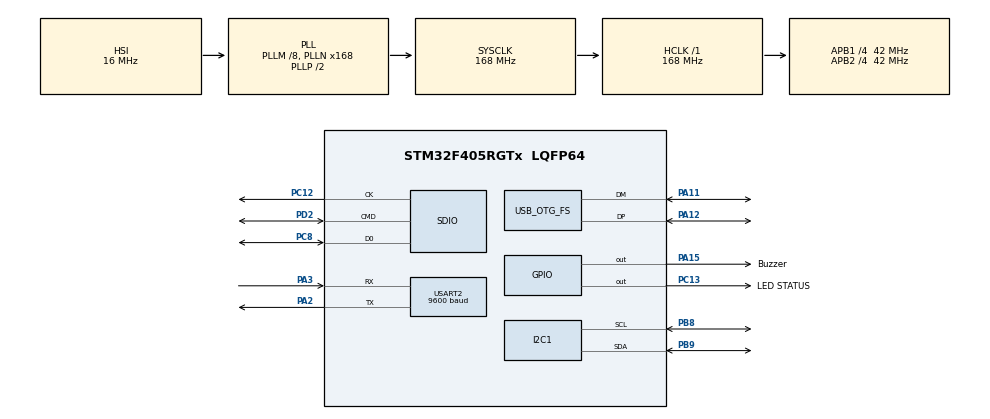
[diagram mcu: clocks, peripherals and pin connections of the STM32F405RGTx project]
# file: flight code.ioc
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Mcu.Family=STM32F4
Mcu.Name=STM32F405RGTx
Mcu.Package=LQFP64
NVIC.OTG_FS_IRQn=true\:0\:0\:false\:false\:true\:false\:true\:true
NVIC.PriorityGroup=NVIC_PRIORITYGROUP_4
NVIC.SDIO_IRQn=true\:0\:0\:false\:false\:true\:true\:true\:true
PA11.Mode=Device_Only
PA11.Signal=USB_OTG_FS_DM
PA12.Mode=Device_Only
PA12.Signal=USB_OTG_FS_DP
PA13.Mode=Serial_Wire
PA13.Signal=SYS_JTMS-SWDIO
PA14.Mode=Serial_Wire
PA14.Signal=SYS_JTCK-SWCLK
PA15.GPIO_Label=Buzzer
PA15.GPIO_ModeDefaultOutputPP=GPIO_MODE_OUTPUT_PP
PA15.Signal=GPIO_Output
PA2.Mode=Asynchronous
PA2.Signal=USART2_TX
PA3.Mode=Asynchronous
PA3.Signal=USART2_RX
PB8.Mode=I2C
PB8.Signal=I2C1_SCL
PB9.Mode=I2C
PB9.Signal=I2C1_SDA
PC12.Mode=SD_1_bit
PC12.Signal=SDIO_CK
PC13-ANTI_TAMP.GPIO_Label=LED STATUS
PC13-ANTI_TAMP.Signal=GPIO_Output
PC8.GPIO_PuPd=GPIO_PULLUP
PC8.Mode=SD_1_bit
PC8.Signal=SDIO_D0
PD2.GPIO_PuPd=GPIO_PULLUP
PD2.Mode=SD_1_bit
PD2.Signal=SDIO_CMD
ProjectManager.HeapSize=0x200
ProjectManager.StackSize=0x400
ProjectManager.TargetToolchain=STM32CubeIDE
RCC.48MHZClocksFreq_Value=48000000
RCC.AHBFreq_Value=168000000
RCC.APB1CLKDivider=RCC_HCLK_DIV4
RCC.APB1Freq_Value=42000000
RCC.APB1TimFreq_Value=84000000
RCC.APB2CLKDivider=RCC_HCLK_DIV4
RCC.APB2Freq_Value=42000000
RCC.APB2TimFreq_Value=84000000
RCC.CortexFreq_Value=168000000
RCC.HCLKFreq_Value=168000000
RCC.HSE_VALUE=8000000
RCC.HSI_VALUE=16000000
RCC.LSE_VALUE=32768
RCC.PLLM=8
RCC.PLLN=168
RCC.PLLQ=7
RCC.PLLSource=RCC_PLLSOURCE_HSI
RCC.SYSCLKFreq_VALUE=168000000
RCC.SYSCLKSource=RCC_SYSCLKSOURCE_PLLCLK
RCC.VCOOutputFreq_Value=336000000
SDIO.ClockDiv=118
USART2.BaudRate=9600
USART2.VirtualMode=VM_ASYNC
USB_DEVICE.CLASS_NAME_FS=CDC
USB_DEVICE.VirtualMode-CDC_FS=Cdc
USB_DEVICE.VirtualModeFS=Cdc_FS
USB_OTG_FS.VirtualMode=Device_Only
VP_FATFS_VS_SDIO.Mode=SDIO
VP_USB_DEVICE_VS_USB_DEVICE_CDC_FS.Mode=CDC_FS
board=custom

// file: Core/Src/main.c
/* USER CODE BEGIN Header */
/**
  ******************************************************************************
  * @file           : main.c
  * @brief          : Main program body
  ******************************************************************************
  * @attention
  *
  * Copyright (c) 2026 STMicroelectronics.
  * All rights reserved.
  *
  * This software is licensed under terms that can be found in the LICENSE file
  * in the root directory of this software component.
  * If no LICENSE file comes with this software, it is provided AS-IS.
  *
  ******************************************************************************
  */
/* USER CODE END Header */
#include "main.h"
#include "usb_device.h"
#include "usbd_cdc_if.h"
#include "flight_app.h"
#include <stdio.h>
#include "fatfs.h"

I2C_HandleTypeDef hi2c1;

SD_HandleTypeDef hsd;

UART_HandleTypeDef huart2;

void SystemClock_Config(void);
static void MX_GPIO_Init(void);
static void MX_I2C1_Init(void);
static void MX_USART2_UART_Init(void);
static void MX_SDIO_SD_Init(void);

/* USER CODE BEGIN 0 */
int _write(int file, char *ptr, int len)
{
    uint32_t start = HAL_GetTick();

    while (CDC_Transmit_FS((uint8_t *)ptr, len) == USBD_BUSY)
    {
        if ((HAL_GetTick() - start) > 20U)
        {
            /* Drop message if USB is busy too long */
            return len;
        }
    }
    return len;
}

/* USER CODE END 0 */

int main(void)
{

  /* MCU Configuration--------------------------------------------------------*/

  /* Reset of all peripherals, Initializes the Flash interface and the Systick. */
  HAL_Init();

  /* Configure the system clock */
  SystemClock_Config();

  /* Initialize all configured peripherals */
  MX_GPIO_Init();
  MX_USB_DEVICE_Init();
  MX_I2C1_Init();
  MX_USART2_UART_Init();
  MX_SDIO_SD_Init();
  MX_FATFS_Init();
  /* USER CODE BEGIN 2 */
  HAL_Delay(2000);

  printf("Booting flight project...\r\n");

  /* Start application layer */
  FlightApp_Init();
  /* USER CODE END 2 */

  /* Infinite loop */
  while (1)
  {
	  FlightApp_Run();
  }
}

void SystemClock_Config(void)
{
  RCC_OscInitTypeDef RCC_OscInitStruct = {0};
  RCC_ClkInitTypeDef RCC_ClkInitStruct = {0};

  /** Configure the main internal regulator output voltage
  */
  __HAL_RCC_PWR_CLK_ENABLE();
  __HAL_PWR_VOLTAGESCALING_CONFIG(PWR_REGULATOR_VOLTAGE_SCALE1);

  /** Initializes the RCC Oscillators according to the specified parameters
  * in the RCC_OscInitTypeDef structure.
  */
  RCC_OscInitStruct.OscillatorType = RCC_OSCILLATORTYPE_HSI;
  RCC_OscInitStruct.HSIState = RCC_HSI_ON;
  RCC_OscInitStruct.HSICalibrationValue = RCC_HSICALIBRATION_DEFAULT;
  RCC_OscInitStruct.PLL.PLLState = RCC_PLL_ON;
  RCC_OscInitStruct.PLL.PLLSource = RCC_PLLSOURCE_HSI;
  RCC_OscInitStruct.PLL.PLLM = 8;
  RCC_OscInitStruct.PLL.PLLN = 168;
  RCC_OscInitStruct.PLL.PLLP = RCC_PLLP_DIV2;
  RCC_OscInitStruct.PLL.PLLQ = 7;
  if (HAL_RCC_OscConfig(&RCC_OscInitStruct) != HAL_OK)
  {
    Error_Handler();
  }

  /** Initializes the CPU, AHB and APB buses clocks
  */
  RCC_ClkInitStruct.ClockType = RCC_CLOCKTYPE_HCLK|RCC_CLOCKTYPE_SYSCLK
                              |RCC_CLOCKTYPE_PCLK1|RCC_CLOCKTYPE_PCLK2;
  RCC_ClkInitStruct.SYSCLKSource = RCC_SYSCLKSOURCE_PLLCLK;
  RCC_ClkInitStruct.AHBCLKDivider = RCC_SYSCLK_DIV1;
  RCC_ClkInitStruct.APB1CLKDivider = RCC_HCLK_DIV4;
  RCC_ClkInitStruct.APB2CLKDivider = RCC_HCLK_DIV4;

  if (HAL_RCC_ClockConfig(&RCC_ClkInitStruct, FLASH_LATENCY_5) != HAL_OK)
  {
    Error_Handler();
  }
}

static void MX_I2C1_Init(void)
{

  hi2c1.Instance = I2C1;
  hi2c1.Init.ClockSpeed = 100000;
  hi2c1.Init.DutyCycle = I2C_DUTYCYCLE_2;
  hi2c1.Init.OwnAddress1 = 0;
  hi2c1.Init.AddressingMode = I2C_ADDRESSINGMODE_7BIT;
  hi2c1.Init.DualAddressMode = I2C_DUALADDRESS_DISABLE;
  hi2c1.Init.OwnAddress2 = 0;
  hi2c1.Init.GeneralCallMode = I2C_GENERALCALL_DISABLE;
  hi2c1.Init.NoStretchMode = I2C_NOSTRETCH_DISABLE;
  if (HAL_I2C_Init(&hi2c1) != HAL_OK)
  {
    Error_Handler();
  }

}

static void MX_SDIO_SD_Init(void)
{

  hsd.Instance = SDIO;
  hsd.Init.ClockEdge = SDIO_CLOCK_EDGE_RISING;
  hsd.Init.ClockBypass = SDIO_CLOCK_BYPASS_DISABLE;
  hsd.Init.ClockPowerSave = SDIO_CLOCK_POWER_SAVE_DISABLE;
  hsd.Init.BusWide = SDIO_BUS_WIDE_1B;
  hsd.Init.HardwareFlowControl = SDIO_HARDWARE_FLOW_CONTROL_DISABLE;
  hsd.Init.ClockDiv = 118;

}

static void MX_USART2_UART_Init(void)
{

  huart2.Instance = USART2;
  huart2.Init.BaudRate = 9600;
  huart2.Init.WordLength = UART_WORDLENGTH_8B;
  huart2.Init.StopBits = UART_STOPBITS_1;
  huart2.Init.Parity = UART_PARITY_NONE;
  huart2.Init.Mode = UART_MODE_TX_RX;
  huart2.Init.HwFlowCtl = UART_HWCONTROL_NONE;
  huart2.Init.OverSampling = UART_OVERSAMPLING_16;
  if (HAL_UART_Init(&huart2) != HAL_OK)
  {
    Error_Handler();
  }

}

static void MX_GPIO_Init(void)
{
  GPIO_InitTypeDef GPIO_InitStruct = {0};

  /* GPIO Ports Clock Enable */
  __HAL_RCC_GPIOC_CLK_ENABLE();
  __HAL_RCC_GPIOA_CLK_ENABLE();
  __HAL_RCC_GPIOD_CLK_ENABLE();
  __HAL_RCC_GPIOB_CLK_ENABLE();

  /*Configure GPIO pin Output Level */
  HAL_GPIO_WritePin(LED_STATUS_GPIO_Port, LED_STATUS_Pin, GPIO_PIN_RESET);

  /*Configure GPIO pin Output Level */
  HAL_GPIO_WritePin(Buzzer_GPIO_Port, Buzzer_Pin, GPIO_PIN_RESET);

  /*Configure GPIO pin : LED_STATUS_Pin */
  GPIO_InitStruct.Pin = LED_STATUS_Pin;
  GPIO_InitStruct.Mode = GPIO_MODE_OUTPUT_PP;
  GPIO_InitStruct.Pull = GPIO_NOPULL;
  GPIO_InitStruct.Speed = GPIO_SPEED_FREQ_LOW;
  HAL_GPIO_Init(LED_STATUS_GPIO_Port, &GPIO_InitStruct);

  /*Configure GPIO pin : Buzzer_Pin */
  GPIO_InitStruct.Pin = Buzzer_Pin;
  GPIO_InitStruct.Mode = GPIO_MODE_OUTPUT_PP;
  GPIO_InitStruct.Pull = GPIO_NOPULL;
  GPIO_InitStruct.Speed = GPIO_SPEED_FREQ_LOW;
  HAL_GPIO_Init(Buzzer_GPIO_Port, &GPIO_InitStruct);

}

void Error_Handler(void)
{
  __disable_irq();
  while (1)
  {
  }
}
